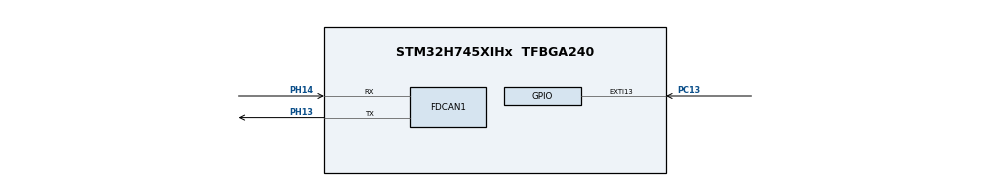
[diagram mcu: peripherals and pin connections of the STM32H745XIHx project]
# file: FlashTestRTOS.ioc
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CORTEX_M7.AccessPermission-Cortex_Memory_Protection_Unit_Region0_Settings=MPU_REGION_FULL_ACCESS
CORTEX_M7.AccessPermission-Cortex_Memory_Protection_Unit_Region1_Settings=MPU_REGION_FULL_ACCESS
CORTEX_M7.BaseAddress-Cortex_Memory_Protection_Unit_Region0_Settings=0xD0000000
CORTEX_M7.BaseAddress-Cortex_Memory_Protection_Unit_Region1_Settings=0x08100000
CORTEX_M7.CPU_DCache=Enabled
CORTEX_M7.CPU_ICache=Enabled
CORTEX_M7.DisableExec-Cortex_Memory_Protection_Unit_Region0_Settings=MPU_INSTRUCTION_ACCESS_DISABLE
CORTEX_M7.DisableExec-Cortex_Memory_Protection_Unit_Region1_Settings=MPU_INSTRUCTION_ACCESS_DISABLE
CORTEX_M7.Enable-Cortex_Memory_Protection_Unit_Region0_Settings=MPU_REGION_ENABLE
CORTEX_M7.Enable-Cortex_Memory_Protection_Unit_Region1_Settings=MPU_REGION_ENABLE
CORTEX_M7.IsBufferable-Cortex_Memory_Protection_Unit_Region0_Settings=MPU_ACCESS_BUFFERABLE
CORTEX_M7.IsBufferable-Cortex_Memory_Protection_Unit_Region1_Settings=MPU_ACCESS_BUFFERABLE
CORTEX_M7.IsCacheable-Cortex_Memory_Protection_Unit_Region0_Settings=MPU_ACCESS_CACHEABLE
CORTEX_M7.IsCacheable-Cortex_Memory_Protection_Unit_Region1_Settings=MPU_ACCESS_CACHEABLE
CORTEX_M7.IsShareable-Cortex_Memory_Protection_Unit_Region1_Settings=MPU_ACCESS_NOT_SHAREABLE
CORTEX_M7.MPU_Control=MPU_PRIVILEGED_DEFAULT
CORTEX_M7.Size-Cortex_Memory_Protection_Unit_Region0_Settings=MPU_REGION_SIZE_1MB
CORTEX_M7.Size-Cortex_Memory_Protection_Unit_Region1_Settings=MPU_REGION_SIZE_512KB
CORTEX_M7.default_mode_Activation=1
CortexM4.IPs=FATFS_M4\:I,FREERTOS_M4\:I,IWDG2\:I,RCC,USB_DEVICE_M4\:I,USB_HOST_M4\:I,WWDG2\:I,DMA,BDMA,MDMA,NVIC2\:I,DEBUG,PDM2PCM_M4\:I,PWR,RESMGR_UTILITY,SYS_M4\:I,CORTEX_M4\:I,GPIO,OPENAMP_M4\:I,VREFBUF
CortexM7.IPs=FATFS_M7\:I,FREERTOS_M7\:I,IWDG1\:I,RCC\:I,USB_DEVICE_M7\:I,USB_HOST_M7\:I,WWDG1\:I,DMA\:I,BDMA\:I,MDMA\:I,NVIC1\:I,CORTEX_M7\:I,DEBUG\:I,PDM2PCM_M7\:I,PWR\:I,RESMGR_UTILITY\:I,SYS\:I,GPIO\:I,OPENAMP_M7\:I,VREFBUF\:I,TIM17\:I,emotas.I-CUBE-CANOPEN.1.1.3_M7\:I,FDCAN1\:I
CortexM7.Pins=PC13
FDCAN1.CalculateBaudRateNominal=625000
FDCAN1.CalculateTimeBitNominal=1600
FDCAN1.CalculateTimeQuantumNominal=320.0
FREERTOS_M7.HEAP_NUMBER=4
FREERTOS_M7.Tasks01=defaultTask,24,128,StartDefaultTask,Default,NULL,Dynamic,NULL,NULL
FREERTOS_M7.configENABLE_FPU=1
Mcu.Family=STM32H7
Mcu.Name=STM32H745XIHx
Mcu.Package=TFBGA240
NVIC1.EXTI15_10_IRQn=true\:5\:0\:false\:false\:true\:true\:true\:true\:true
NVIC1.PriorityGroup=NVIC_PRIORITYGROUP_4
NVIC1.TIM17_IRQn=true\:15\:0\:false\:false\:true\:false\:false\:true\:true
NVIC1.TimeBase=TIM17_IRQn
NVIC1.TimeBaseIP=TIM17
NVIC2.PriorityGroup=NVIC_PRIORITYGROUP_4
PC13.PinAttribute=CortexM7
PC13.Signal=GPXTI13
PH0-OSC_IN\ (PH0).Mode=HSE-External-Oscillator
PH0-OSC_IN\ (PH0).PinAttribute=CortexM7
PH0-OSC_IN\ (PH0).Signal=RCC_OSC_IN
PH1-OSC_OUT\ (PH1).Mode=HSE-External-Oscillator
PH1-OSC_OUT\ (PH1).PinAttribute=CortexM7
PH1-OSC_OUT\ (PH1).Signal=RCC_OSC_OUT
PH13.Mode=FDCAN_Activate
PH13.PinAttribute=CortexM7
PH13.Signal=FDCAN1_TX
PH14.Mode=FDCAN_Activate
PH14.PinAttribute=CortexM7
PH14.Signal=FDCAN1_RX
ProjectManager.HeapSize=M4-0x200,M7-0x200
ProjectManager.StackSize=M4-0x400,M7-0x400
ProjectManager.TargetToolchain=MDK-ARM V5.27
RCC.ADCFreq_Value=50390625
RCC.APB1Freq_Value=100000000
RCC.APB2Freq_Value=100000000
RCC.APB3Freq_Value=100000000
RCC.APB4Freq_Value=100000000
RCC.CortexFreq_Value=400000000
RCC.D1PPRE=RCC_APB3_DIV2
RCC.D2PPRE1=RCC_APB1_DIV2
RCC.D2PPRE2=RCC_APB2_DIV2
RCC.D3PPRE=RCC_APB4_DIV2
RCC.DIVM1=5
RCC.DIVN1=160
RCC.DIVQ1=16
RCC.DIVR1=4
RCC.HCLKFreq_Value=200000000
RCC.HPRE=RCC_HCLK_DIV2
RCC.PLL2FRACN=0
RCC.PLL3FRACN=0
RCC.PLLFRACN=0
RCC.PLLSourceVirtual=RCC_PLLSOURCE_HSE
RCC.PWR_Regulator_Voltage_Scale=PWR_REGULATOR_VOLTAGE_SCALE1
RCC.SYSCLKFreq_VALUE=400000000
RCC.SYSCLKSource=RCC_SYSCLKSOURCE_PLLCLK
RCC.SupplySource=PWR_DIRECT_SMPS_SUPPLY
RCC.USBFreq_Value=50000000
VP_FREERTOS_M7_VS_CMSIS_V2.Mode=CMSIS_V2
VP_SYS_M4_VS_Systick.Mode=SysTick
VP_SYS_VS_tim17.Mode=TIM17
VP_emotas.I-CUBE-CANOPEN_M7_VS_CANopenJjemotasIiCANopen_3.8.0_1.1.3.Mode=CANopenJjemotasIiCANopen
VP_emotas.I-CUBE-CANOPEN_M7_VS_DeviceJjApplication_1.0.0_1.1.3.Mode=DeviceJjApplication
board=STM32H745I-DISCO
emotas.I-CUBE-CANOPEN.1.1.3_M7.CANopenJjemotasIiCANopen=true
emotas.I-CUBE-CANOPEN.1.1.3_M7.DeviceJjApplication=Slave

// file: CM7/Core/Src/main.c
/* USER CODE BEGIN Header */
/**
  ******************************************************************************
  * @file           : main.c
  * @brief          : Main program body
  ******************************************************************************
  * @attention
  *
  * Copyright (c) 2023 STMicroelectronics.
  * All rights reserved.
  *
  * This software is licensed under terms that can be found in the LICENSE file
  * in the root directory of this software component.
  * If no LICENSE file comes with this software, it is provided AS-IS.
  *
  ******************************************************************************
  */
/* USER CODE END Header */
#include "main.h"
#include "cmsis_os.h"
#include "app_canopen.h"

/* USER CODE BEGIN Includes */
#include "memory_management.h"

/* USER CODE END Includes */

/* USER CODE BEGIN PD */

#ifndef HSEM_ID_0
#define HSEM_ID_0 (0U) /* HW semaphore 0*/
#endif
/* USER CODE END PD */

FDCAN_HandleTypeDef hfdcan1;

/* Definitions for defaultTask */
osThreadId_t defaultTaskHandle;
const osThreadAttr_t defaultTask_attributes = {
  .name = "defaultTask",
  .stack_size = 128 * 4,
  .priority = (osPriority_t) osPriorityNormal,
};
/* USER CODE BEGIN PV */
uint32_t value;
uint32_t flashdata[8];
const uint32_t code=0x67818301;

uint32_t	*data=flashdata;

osThreadId_t id_myTask;
/* USER CODE END PV */

void SystemClock_Config(void);
static void MPU_Config(void);
static void MX_GPIO_Init(void);
static void MX_FDCAN1_Init(void);
void StartDefaultTask(void *argument);

/* USER CODE BEGIN PFP */

void myTask(void *argument);

/* USER CODE END PFP */

int main(void)
{
/* USER CODE BEGIN Boot_Mode_Sequence_0 */
  int32_t timeout;
/* USER CODE END Boot_Mode_Sequence_0 */

  /* MPU Configuration--------------------------------------------------------*/
  MPU_Config();

  /* Enable I-Cache---------------------------------------------------------*/
  SCB_EnableICache();

  /* Enable D-Cache---------------------------------------------------------*/
  SCB_EnableDCache();

/* USER CODE BEGIN Boot_Mode_Sequence_1 */
  /* Wait until CPU2 boots and enters in stop mode or timeout*/
/* USER CODE END Boot_Mode_Sequence_1 */
  /* MCU Configuration--------------------------------------------------------*/

  /* Reset of all peripherals, Initializes the Flash interface and the Systick. */
  HAL_Init();

  /* Configure the system clock */
  SystemClock_Config();
/* USER CODE BEGIN Boot_Mode_Sequence_2 */
/* When system initialization is finished, Cortex-M7 will release Cortex-M4 by means of
HSEM notification */
/*HW semaphore Clock enable*/

/* USER CODE END Boot_Mode_Sequence_2 */

  /* Initialize all configured peripherals */
  MX_GPIO_Init();
  MX_FDCAN1_Init();
  MX_CANopen_Init();
  /* USER CODE BEGIN 2 */
	//HAL_NVIC_SetPriorityGrouping(NVIC_PRIORITYGROUP_4);
  /* USER CODE END 2 */

  /* Init scheduler */
  osKernelInitialize();

  /* Create the thread(s) */
  /* creation of defaultTask */
  defaultTaskHandle = osThreadNew(StartDefaultTask, NULL, &defaultTask_attributes);

  /* USER CODE BEGIN RTOS_THREADS */
  id_myTask = osThreadNew(myTask, NULL, NULL);
	osThreadSetPriority(id_myTask, osPriorityAboveNormal);
  /* USER CODE END RTOS_THREADS */

  /* Start scheduler */
  osKernelStart();

  /* We should never get here as control is now taken by the scheduler */
  /* Infinite loop */
  while (1)
  {

  }
}

void SystemClock_Config(void)
{
  RCC_OscInitTypeDef RCC_OscInitStruct = {0};
  RCC_ClkInitTypeDef RCC_ClkInitStruct = {0};

  /** Supply configuration update enable
  */
  HAL_PWREx_ConfigSupply(PWR_DIRECT_SMPS_SUPPLY);

  /** Configure the main internal regulator output voltage
  */
  __HAL_PWR_VOLTAGESCALING_CONFIG(PWR_REGULATOR_VOLTAGE_SCALE1);

  while(!__HAL_PWR_GET_FLAG(PWR_FLAG_VOSRDY)) {}

  /** Initializes the RCC Oscillators according to the specified parameters
  * in the RCC_OscInitTypeDef structure.
  */
  RCC_OscInitStruct.OscillatorType = RCC_OSCILLATORTYPE_HSE;
  RCC_OscInitStruct.HSEState = RCC_HSE_ON;
  RCC_OscInitStruct.PLL.PLLState = RCC_PLL_ON;
  RCC_OscInitStruct.PLL.PLLSource = RCC_PLLSOURCE_HSE;
  RCC_OscInitStruct.PLL.PLLM = 5;
  RCC_OscInitStruct.PLL.PLLN = 160;
  RCC_OscInitStruct.PLL.PLLP = 2;
  RCC_OscInitStruct.PLL.PLLQ = 16;
  RCC_OscInitStruct.PLL.PLLR = 4;
  RCC_OscInitStruct.PLL.PLLRGE = RCC_PLL1VCIRANGE_2;
  RCC_OscInitStruct.PLL.PLLVCOSEL = RCC_PLL1VCOWIDE;
  RCC_OscInitStruct.PLL.PLLFRACN = 0;
  if (HAL_RCC_OscConfig(&RCC_OscInitStruct) != HAL_OK)
  {
    Error_Handler();
  }

  /** Initializes the CPU, AHB and APB buses clocks
  */
  RCC_ClkInitStruct.ClockType = RCC_CLOCKTYPE_HCLK|RCC_CLOCKTYPE_SYSCLK
                              |RCC_CLOCKTYPE_PCLK1|RCC_CLOCKTYPE_PCLK2
                              |RCC_CLOCKTYPE_D3PCLK1|RCC_CLOCKTYPE_D1PCLK1;
  RCC_ClkInitStruct.SYSCLKSource = RCC_SYSCLKSOURCE_PLLCLK;
  RCC_ClkInitStruct.SYSCLKDivider = RCC_SYSCLK_DIV1;
  RCC_ClkInitStruct.AHBCLKDivider = RCC_HCLK_DIV2;
  RCC_ClkInitStruct.APB3CLKDivider = RCC_APB3_DIV2;
  RCC_ClkInitStruct.APB1CLKDivider = RCC_APB1_DIV2;
  RCC_ClkInitStruct.APB2CLKDivider = RCC_APB2_DIV2;
  RCC_ClkInitStruct.APB4CLKDivider = RCC_APB4_DIV2;

  if (HAL_RCC_ClockConfig(&RCC_ClkInitStruct, FLASH_LATENCY_2) != HAL_OK)
  {
    Error_Handler();
  }
}

static void MX_FDCAN1_Init(void)
{

  hfdcan1.Instance = FDCAN1;
  hfdcan1.Init.FrameFormat = FDCAN_FRAME_CLASSIC;
  hfdcan1.Init.Mode = FDCAN_MODE_NORMAL;
  hfdcan1.Init.AutoRetransmission = DISABLE;
  hfdcan1.Init.TransmitPause = DISABLE;
  hfdcan1.Init.ProtocolException = DISABLE;
  hfdcan1.Init.NominalPrescaler = 16;
  hfdcan1.Init.NominalSyncJumpWidth = 1;
  hfdcan1.Init.NominalTimeSeg1 = 2;
  hfdcan1.Init.NominalTimeSeg2 = 2;
  hfdcan1.Init.DataPrescaler = 1;
  hfdcan1.Init.DataSyncJumpWidth = 1;
  hfdcan1.Init.DataTimeSeg1 = 1;
  hfdcan1.Init.DataTimeSeg2 = 1;
  hfdcan1.Init.MessageRAMOffset = 0;
  hfdcan1.Init.StdFiltersNbr = 0;
  hfdcan1.Init.ExtFiltersNbr = 0;
  hfdcan1.Init.RxFifo0ElmtsNbr = 0;
  hfdcan1.Init.RxFifo0ElmtSize = FDCAN_DATA_BYTES_8;
  hfdcan1.Init.RxFifo1ElmtsNbr = 0;
  hfdcan1.Init.RxFifo1ElmtSize = FDCAN_DATA_BYTES_8;
  hfdcan1.Init.RxBuffersNbr = 0;
  hfdcan1.Init.RxBufferSize = FDCAN_DATA_BYTES_8;
  hfdcan1.Init.TxEventsNbr = 0;
  hfdcan1.Init.TxBuffersNbr = 0;
  hfdcan1.Init.TxFifoQueueElmtsNbr = 0;
  hfdcan1.Init.TxFifoQueueMode = FDCAN_TX_FIFO_OPERATION;
  hfdcan1.Init.TxElmtSize = FDCAN_DATA_BYTES_8;
  if (HAL_FDCAN_Init(&hfdcan1) != HAL_OK)
  {
    Error_Handler();
  }

}

static void MX_GPIO_Init(void)
{
  GPIO_InitTypeDef GPIO_InitStruct = {0};

  /* GPIO Ports Clock Enable */
  __HAL_RCC_GPIOH_CLK_ENABLE();
  __HAL_RCC_GPIOC_CLK_ENABLE();

  /*Configure GPIO pin : PC13 */
  GPIO_InitStruct.Pin = GPIO_PIN_13;
  GPIO_InitStruct.Mode = GPIO_MODE_IT_RISING;
  GPIO_InitStruct.Pull = GPIO_NOPULL;
  HAL_GPIO_Init(GPIOC, &GPIO_InitStruct);

  /* EXTI interrupt init*/
  HAL_NVIC_SetPriority(EXTI15_10_IRQn, 5, 0);
  HAL_NVIC_EnableIRQ(EXTI15_10_IRQn);

}

/* USER CODE BEGIN 4 */
void myTask(void *argument)
{
  /* USER CODE BEGIN 5 */

	uint32_t error;

	Flash_Read_Data(0x08100000, data, 8);

	if(flashdata[0]==code)
	{
		value = flashdata[1];
	}
	else
	{
		flashdata[0] = code;
		value = 0;
	}
  /* Infinite loop */
  while(1)
  {
		//osThreadFlagsWait(FLAG_BTN, osFlagsWaitAll, osWaitForever);
		flashdata[1] = value;
		//error = Flash_Write_Data(0x08100000, data, 8);
    //osDelay(10);
  }
  /* USER CODE END 5 */
}

/* USER CODE END 4 */

void StartDefaultTask(void *argument)
{
  /* USER CODE BEGIN 5 */

	uint32_t error;

	Flash_Read_Data(0x08100000, data, 8);

	if(flashdata[0]==code)
	{
		value = flashdata[1];
	}
	else
	{
		flashdata[0] = code;
		value = 0;
	}
  /* Infinite loop */
  while(1)
  {
		//osThreadFlagsWait(FLAG_BTN, osFlagsWaitAll, osWaitForever);
		flashdata[1] = value;
		//error = Flash_Write_Data(0x08100000, data, 8);
    //osDelay(10);
  }
  /* USER CODE END 5 */
}

/* MPU Configuration */

void MPU_Config(void)
{
  MPU_Region_InitTypeDef MPU_InitStruct = {0};

  /* Disables the MPU */
  HAL_MPU_Disable();

  /** Initializes and configures the Region and the memory to be protected
  */
  MPU_InitStruct.Enable = MPU_REGION_ENABLE;
  MPU_InitStruct.Number = MPU_REGION_NUMBER0;
  MPU_InitStruct.BaseAddress = 0x0;
  MPU_InitStruct.Size = MPU_REGION_SIZE_4GB;
  MPU_InitStruct.SubRegionDisable = 0x87;
  MPU_InitStruct.TypeExtField = MPU_TEX_LEVEL0;
  MPU_InitStruct.AccessPermission = MPU_REGION_NO_ACCESS;
  MPU_InitStruct.DisableExec = MPU_INSTRUCTION_ACCESS_DISABLE;
  MPU_InitStruct.IsShareable = MPU_ACCESS_SHAREABLE;
  MPU_InitStruct.IsCacheable = MPU_ACCESS_NOT_CACHEABLE;
  MPU_InitStruct.IsBufferable = MPU_ACCESS_NOT_BUFFERABLE;

  HAL_MPU_ConfigRegion(&MPU_InitStruct);
  /* Enables the MPU */
  HAL_MPU_Enable(MPU_PRIVILEGED_DEFAULT);

}

void HAL_TIM_PeriodElapsedCallback(TIM_HandleTypeDef *htim)
{
  if (htim->Instance == TIM17) {
    HAL_IncTick();
  }
}

void Error_Handler(void)
{
  __disable_irq();
  while (1)
  {
  }
}
